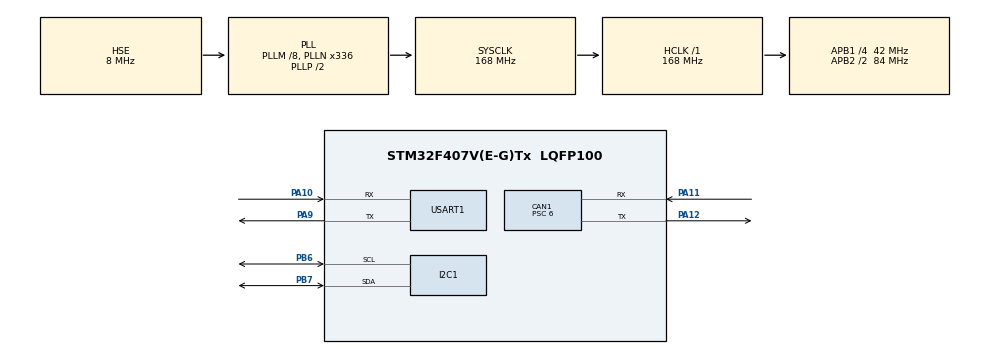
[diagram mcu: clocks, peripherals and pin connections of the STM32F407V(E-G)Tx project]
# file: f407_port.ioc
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CAN1.BS1=CAN_BS1_11TQ
CAN1.BS2=CAN_BS2_2TQ
CAN1.CalculateBaudRate=500000
CAN1.CalculateTimeBit=2000
CAN1.CalculateTimeQuantum=142.85714285714286
CAN1.Prescaler=6
Dma.Request0=USART1_TX
Dma.USART1_TX.0.Direction=DMA_MEMORY_TO_PERIPH
Dma.USART1_TX.0.FIFOMode=DMA_FIFOMODE_DISABLE
Dma.USART1_TX.0.Instance=DMA2_Stream7
Dma.USART1_TX.0.MemDataAlignment=DMA_MDATAALIGN_BYTE
Dma.USART1_TX.0.MemInc=DMA_MINC_ENABLE
Dma.USART1_TX.0.Mode=DMA_NORMAL
Dma.USART1_TX.0.PeriphDataAlignment=DMA_PDATAALIGN_BYTE
Dma.USART1_TX.0.PeriphInc=DMA_PINC_DISABLE
Dma.USART1_TX.0.Priority=DMA_PRIORITY_LOW
FREERTOS.Tasks01=defaultTask,24,128,StartDefaultTask,Default,NULL,Dynamic,NULL,NULL
FREERTOS.configTOTAL_HEAP_SIZE=10240
Mcu.Family=STM32F4
Mcu.Name=STM32F407V(E-G)Tx
Mcu.Package=LQFP100
NVIC.CAN1_RX0_IRQn=true\:5\:0\:false\:false\:true\:true\:true\:true\:true
NVIC.CAN1_SCE_IRQn=true\:5\:0\:false\:false\:true\:true\:true\:true\:true
NVIC.DMA2_Stream7_IRQn=true\:5\:0\:false\:false\:true\:true\:false\:true\:true
NVIC.I2C1_EV_IRQn=true\:5\:0\:false\:false\:true\:true\:true\:true\:true
NVIC.PriorityGroup=NVIC_PRIORITYGROUP_4
NVIC.TIM6_DAC_IRQn=true\:15\:0\:false\:false\:true\:false\:false\:true\:true
NVIC.TimeBase=TIM6_DAC_IRQn
NVIC.TimeBaseIP=TIM6
NVIC.USART1_IRQn=true\:5\:0\:false\:false\:true\:true\:true\:true\:true
PA10.Mode=Asynchronous
PA10.Signal=USART1_RX
PA11.Mode=CAN_Activate
PA11.Signal=CAN1_RX
PA12.Mode=CAN_Activate
PA12.Signal=CAN1_TX
PA13.Mode=Serial_Wire
PA13.Signal=SYS_JTMS-SWDIO
PA14.Mode=Serial_Wire
PA14.Signal=SYS_JTCK-SWCLK
PA9.Mode=Asynchronous
PA9.Signal=USART1_TX
PB6.Mode=I2C
PB6.Signal=I2C1_SCL
PB7.Mode=I2C
PB7.Signal=I2C1_SDA
PH0-OSC_IN.Mode=HSE-External-Oscillator
PH0-OSC_IN.Signal=RCC_OSC_IN
PH1-OSC_OUT.Mode=HSE-External-Oscillator
PH1-OSC_OUT.Signal=RCC_OSC_OUT
ProjectManager.HeapSize=0x200
ProjectManager.StackSize=0x400
ProjectManager.TargetToolchain=CMake
RCC.48MHZClocksFreq_Value=84000000
RCC.AHBFreq_Value=168000000
RCC.APB1CLKDivider=RCC_HCLK_DIV4
RCC.APB1Freq_Value=42000000
RCC.APB1TimFreq_Value=84000000
RCC.APB2CLKDivider=RCC_HCLK_DIV2
RCC.APB2Freq_Value=84000000
RCC.APB2TimFreq_Value=168000000
RCC.CortexFreq_Value=168000000
RCC.HCLKFreq_Value=168000000
RCC.HSE_VALUE=8000000
RCC.HSI_VALUE=16000000
RCC.LSE_VALUE=32768
RCC.PLLM=8
RCC.PLLN=336
RCC.PLLSourceVirtual=RCC_PLLSOURCE_HSE
RCC.SYSCLKFreq_VALUE=168000000
RCC.SYSCLKSource=RCC_SYSCLKSOURCE_PLLCLK
RCC.VCOOutputFreq_Value=336000000
USART1.VirtualMode=VM_ASYNC
VP_FREERTOS_VS_CMSIS_V2.Mode=CMSIS_V2
VP_SYS_VS_tim6.Mode=TIM6
board=custom

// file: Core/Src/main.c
/* USER CODE BEGIN Header */
/**
  ******************************************************************************
  * @file           : main.c
  * @brief          : Main program body
  ******************************************************************************
  * @attention
  *
  * Copyright (c) 2026 STMicroelectronics.
  * All rights reserved.
  *
  * This software is licensed under terms that can be found in the LICENSE file
  * in the root directory of this software component.
  * If no LICENSE file comes with this software, it is provided AS-IS.
  *
  ******************************************************************************
  */
/* USER CODE END Header */
#include "main.h"
#include "cmsis_os.h"

/* USER CODE BEGIN Includes */
#include <stdio.h>

/* USER CODE END Includes */

CAN_HandleTypeDef hcan1;

I2C_HandleTypeDef hi2c1;

UART_HandleTypeDef huart1;
DMA_HandleTypeDef hdma_usart1_tx;

/* Definitions for defaultTask */
osThreadId_t defaultTaskHandle;
const osThreadAttr_t defaultTask_attributes = {
  .name = "defaultTask",
  .stack_size = 128 * 4,
  .priority = (osPriority_t) osPriorityNormal,
};

void SystemClock_Config(void);
static void MX_GPIO_Init(void);
static void MX_DMA_Init(void);
static void MX_USART1_UART_Init(void);
static void MX_CAN1_Init(void);
static void MX_I2C1_Init(void);
void StartDefaultTask(void *argument);

int main(void)
{

  /* MCU Configuration--------------------------------------------------------*/

  /* Reset of all peripherals, Initializes the Flash interface and the Systick. */
  HAL_Init();

  /* Configure the system clock */
  SystemClock_Config();

  /* Initialize all configured peripherals */
  MX_GPIO_Init();
  MX_DMA_Init();
  MX_USART1_UART_Init();
  MX_CAN1_Init();
  MX_I2C1_Init();
  /* USER CODE BEGIN 2 */
  /* 移植自 F103：先打印时钟树，再初始化应用层（C++17，HAL-free） */
  printf("\r\n===== F407 port boot =====\r\n");
  printf("SYSCLK=%lu HCLK=%lu PCLK1=%lu PCLK2=%lu\r\n",
         (unsigned long)HAL_RCC_GetSysClockFreq(),
         (unsigned long)HAL_RCC_GetHCLKFreq(),
         (unsigned long)HAL_RCC_GetPCLK1Freq(),
         (unsigned long)HAL_RCC_GetPCLK2Freq());
  extern void app_init(void);
  app_init();
  /* USER CODE END 2 */

  /* Init scheduler */
  osKernelInitialize();

  /* Create the thread(s) */
  /* creation of defaultTask */
  defaultTaskHandle = osThreadNew(StartDefaultTask, NULL, &defaultTask_attributes);

  /* Start scheduler */
  osKernelStart();

  /* We should never get here as control is now taken by the scheduler */

  /* Infinite loop */
  while (1)
  {

  }
}

void SystemClock_Config(void)
{
  RCC_OscInitTypeDef RCC_OscInitStruct = {0};
  RCC_ClkInitTypeDef RCC_ClkInitStruct = {0};

  /** Configure the main internal regulator output voltage
  */
  __HAL_RCC_PWR_CLK_ENABLE();
  __HAL_PWR_VOLTAGESCALING_CONFIG(PWR_REGULATOR_VOLTAGE_SCALE1);

  /** Initializes the RCC Oscillators according to the specified parameters
  * in the RCC_OscInitTypeDef structure.
  */
  RCC_OscInitStruct.OscillatorType = RCC_OSCILLATORTYPE_HSE;
  RCC_OscInitStruct.HSEState = RCC_HSE_ON;
  RCC_OscInitStruct.PLL.PLLState = RCC_PLL_ON;
  RCC_OscInitStruct.PLL.PLLSource = RCC_PLLSOURCE_HSE;
  RCC_OscInitStruct.PLL.PLLM = 8;
  RCC_OscInitStruct.PLL.PLLN = 336;
  RCC_OscInitStruct.PLL.PLLP = RCC_PLLP_DIV2;
  RCC_OscInitStruct.PLL.PLLQ = 4;
  if (HAL_RCC_OscConfig(&RCC_OscInitStruct) != HAL_OK)
  {
    Error_Handler();
  }

  /** Initializes the CPU, AHB and APB buses clocks
  */
  RCC_ClkInitStruct.ClockType = RCC_CLOCKTYPE_HCLK|RCC_CLOCKTYPE_SYSCLK
                              |RCC_CLOCKTYPE_PCLK1|RCC_CLOCKTYPE_PCLK2;
  RCC_ClkInitStruct.SYSCLKSource = RCC_SYSCLKSOURCE_PLLCLK;
  RCC_ClkInitStruct.AHBCLKDivider = RCC_SYSCLK_DIV1;
  RCC_ClkInitStruct.APB1CLKDivider = RCC_HCLK_DIV4;
  RCC_ClkInitStruct.APB2CLKDivider = RCC_HCLK_DIV2;

  if (HAL_RCC_ClockConfig(&RCC_ClkInitStruct, FLASH_LATENCY_5) != HAL_OK)
  {
    Error_Handler();
  }
}

static void MX_CAN1_Init(void)
{

  hcan1.Instance = CAN1;
  hcan1.Init.Prescaler = 6;
  hcan1.Init.Mode = CAN_MODE_NORMAL;
  hcan1.Init.SyncJumpWidth = CAN_SJW_1TQ;
  hcan1.Init.TimeSeg1 = CAN_BS1_11TQ;
  hcan1.Init.TimeSeg2 = CAN_BS2_2TQ;
  hcan1.Init.TimeTriggeredMode = DISABLE;
  hcan1.Init.AutoBusOff = DISABLE;
  hcan1.Init.AutoWakeUp = DISABLE;
  hcan1.Init.AutoRetransmission = DISABLE;
  hcan1.Init.ReceiveFifoLocked = DISABLE;
  hcan1.Init.TransmitFifoPriority = DISABLE;
  if (HAL_CAN_Init(&hcan1) != HAL_OK)
  {
    Error_Handler();
  }

}

static void MX_I2C1_Init(void)
{

  hi2c1.Instance = I2C1;
  hi2c1.Init.ClockSpeed = 100000;
  hi2c1.Init.DutyCycle = I2C_DUTYCYCLE_2;
  hi2c1.Init.OwnAddress1 = 0;
  hi2c1.Init.AddressingMode = I2C_ADDRESSINGMODE_7BIT;
  hi2c1.Init.DualAddressMode = I2C_DUALADDRESS_DISABLE;
  hi2c1.Init.OwnAddress2 = 0;
  hi2c1.Init.GeneralCallMode = I2C_GENERALCALL_DISABLE;
  hi2c1.Init.NoStretchMode = I2C_NOSTRETCH_DISABLE;
  if (HAL_I2C_Init(&hi2c1) != HAL_OK)
  {
    Error_Handler();
  }

}

static void MX_USART1_UART_Init(void)
{

  huart1.Instance = USART1;
  huart1.Init.BaudRate = 115200;
  huart1.Init.WordLength = UART_WORDLENGTH_8B;
  huart1.Init.StopBits = UART_STOPBITS_1;
  huart1.Init.Parity = UART_PARITY_NONE;
  huart1.Init.Mode = UART_MODE_TX_RX;
  huart1.Init.HwFlowCtl = UART_HWCONTROL_NONE;
  huart1.Init.OverSampling = UART_OVERSAMPLING_16;
  if (HAL_UART_Init(&huart1) != HAL_OK)
  {
    Error_Handler();
  }

}

static void MX_DMA_Init(void)
{

  /* DMA controller clock enable */
  __HAL_RCC_DMA2_CLK_ENABLE();

  /* DMA interrupt init */
  /* DMA2_Stream7_IRQn interrupt configuration */
  HAL_NVIC_SetPriority(DMA2_Stream7_IRQn, 5, 0);
  HAL_NVIC_EnableIRQ(DMA2_Stream7_IRQn);

}

static void MX_GPIO_Init(void)
{

  /* GPIO Ports Clock Enable */
  __HAL_RCC_GPIOH_CLK_ENABLE();
  __HAL_RCC_GPIOA_CLK_ENABLE();
  __HAL_RCC_GPIOB_CLK_ENABLE();

}

/* USER CODE BEGIN 4 */
/* printf 落地：newlib 的 _write() 逐字节调用 __io_putchar()（见 syscalls.c） */
/* 真正的发送在 bsp 层，这样上层完全看不到 HAL_UART_* */
extern int bsp_uart1_putchar(int ch);

int __io_putchar(int ch)
{
  return bsp_uart1_putchar(ch);
}

/* 给 C 代码用的日志入口（main.c 里的任务通过它打日志） */
extern void common_log_info(const char* fmt, ...);

/* USER CODE END 4 */

void StartDefaultTask(void *argument)
{
  for(;;)
  {
    osDelay(1);
  }
}

void HAL_TIM_PeriodElapsedCallback(TIM_HandleTypeDef *htim)
{
  if (htim->Instance == TIM6)
  {
    HAL_IncTick();
  }
}

void Error_Handler(void)
{
  __disable_irq();
  while (1)
  {
  }
}
